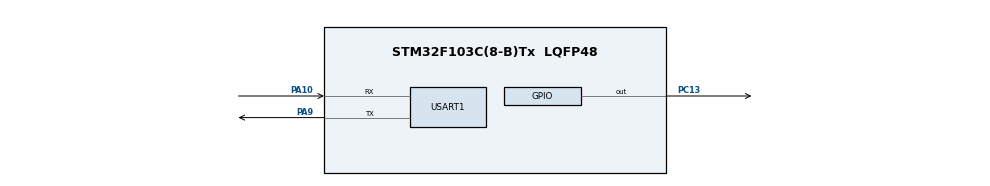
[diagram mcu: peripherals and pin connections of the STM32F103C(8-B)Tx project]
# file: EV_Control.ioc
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Mcu.Family=STM32F1
Mcu.Name=STM32F103C(8-B)Tx
Mcu.Package=LQFP48
NVIC.PriorityGroup=NVIC_PRIORITYGROUP_4
PA10.Mode=Asynchronous
PA10.Signal=USART1_RX
PA9.Mode=Asynchronous
PA9.Signal=USART1_TX
PC13-TAMPER-RTC.Signal=GPIO_Output
ProjectManager.HeapSize=0x200
ProjectManager.StackSize=0x400
ProjectManager.TargetToolchain=STM32CubeIDE
RCC.APB1Freq_Value=8000000
RCC.APB2Freq_Value=8000000
USART1.VirtualMode=VM_ASYNC
VP_SYS_VS_ND.Mode=No_Debug
board=custom

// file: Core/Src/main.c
/* USER CODE BEGIN Header */
/**
  ******************************************************************************
  * @file           : main.c
  * @brief          : Main program body
  ******************************************************************************
  * @attention
  *
  * Copyright (c) 2026 STMicroelectronics.
  * All rights reserved.
  *
  * This software is licensed under terms that can be found in the LICENSE file
  * in the root directory of this software component.
  * If no LICENSE file comes with this software, it is provided AS-IS.
  *
  ******************************************************************************
  */
/* USER CODE END Header */
#include "main.h"

/* USER CODE BEGIN Includes */
#include "ev_control.h"
#include <stdio.h>
/* USER CODE END Includes */

UART_HandleTypeDef huart1;

/* USER CODE BEGIN PV */
EV_State_t ev;
static uint32_t uart_counter = 0;
/* USER CODE END PV */

void SystemClock_Config(void);
static void MX_GPIO_Init(void);
static void MX_USART1_UART_Init(void);
/* USER CODE BEGIN PFP */
static void UART_Print_EV_State(float accel_pct, float brake_pct);
static const char* DriveMode_ToString(DriveMode_t mode);
/* USER CODE END PFP */

int main(void)
{

  /* MCU Configuration--------------------------------------------------------*/

  /* Reset of all peripherals, Initializes the Flash interface and the Systick. */
  HAL_Init();

  /* Configure the system clock */
  SystemClock_Config();

  /* Initialize all configured peripherals */
  MX_GPIO_Init();
  MX_USART1_UART_Init();
  /* USER CODE BEGIN 2 */
  EV_Init(&ev);

  const char start_msg[] = "EV_Control demo started\r\n";
  HAL_UART_Transmit(&huart1, (uint8_t*)start_msg, sizeof(start_msg) - 1U, 100);
  /* USER CODE END 2 */

  /* Infinite loop */
  while (1)
  {

    /* USER CODE BEGIN 3 */
    uint32_t phase_ms;
    float accel_pct;
    float brake_pct;

    phase_ms = HAL_GetTick() % 28000U;

    if (phase_ms < 8000U)
    {
      EV_SetDriveMode(&ev, DRIVE_NORMAL);
      accel_pct = 50.0f;
      brake_pct = 0.0f;
    }
    else if (phase_ms < 12000U)
    {
      EV_SetDriveMode(&ev, DRIVE_NORMAL);
      accel_pct = 0.0f;
      brake_pct = 80.0f;
    }
    else if (phase_ms < 20000U)
    {
      EV_SetDriveMode(&ev, DRIVE_SPORT);
      accel_pct = 70.0f;
      brake_pct = 0.0f;
    }
    else
    {
      EV_SetDriveMode(&ev, DRIVE_ECO);
      accel_pct = 40.0f;
      brake_pct = 0.0f;
    }

    EV_Update(&ev, accel_pct, brake_pct, 0.01f);

    uart_counter++;
    if (uart_counter >= 50U)
    {
      uart_counter = 0U;
      HAL_GPIO_TogglePin(GPIOC, GPIO_PIN_13);
      UART_Print_EV_State(accel_pct, brake_pct);
    }

    HAL_Delay(10);
  }
  /* USER CODE END 3 */
}

void SystemClock_Config(void)
{
  RCC_OscInitTypeDef RCC_OscInitStruct = {0};
  RCC_ClkInitTypeDef RCC_ClkInitStruct = {0};

  /** Initializes the RCC Oscillators according to the specified parameters
  * in the RCC_OscInitTypeDef structure.
  */
  RCC_OscInitStruct.OscillatorType = RCC_OSCILLATORTYPE_HSI;
  RCC_OscInitStruct.HSIState = RCC_HSI_ON;
  RCC_OscInitStruct.HSICalibrationValue = RCC_HSICALIBRATION_DEFAULT;
  RCC_OscInitStruct.PLL.PLLState = RCC_PLL_NONE;
  if (HAL_RCC_OscConfig(&RCC_OscInitStruct) != HAL_OK)
  {
    Error_Handler();
  }

  /** Initializes the CPU, AHB and APB buses clocks
  */
  RCC_ClkInitStruct.ClockType = RCC_CLOCKTYPE_HCLK|RCC_CLOCKTYPE_SYSCLK
                              |RCC_CLOCKTYPE_PCLK1|RCC_CLOCKTYPE_PCLK2;
  RCC_ClkInitStruct.SYSCLKSource = RCC_SYSCLKSOURCE_HSI;
  RCC_ClkInitStruct.AHBCLKDivider = RCC_SYSCLK_DIV1;
  RCC_ClkInitStruct.APB1CLKDivider = RCC_HCLK_DIV1;
  RCC_ClkInitStruct.APB2CLKDivider = RCC_HCLK_DIV1;

  if (HAL_RCC_ClockConfig(&RCC_ClkInitStruct, FLASH_LATENCY_0) != HAL_OK)
  {
    Error_Handler();
  }
}

static void MX_USART1_UART_Init(void)
{

  huart1.Instance = USART1;
  huart1.Init.BaudRate = 115200;
  huart1.Init.WordLength = UART_WORDLENGTH_8B;
  huart1.Init.StopBits = UART_STOPBITS_1;
  huart1.Init.Parity = UART_PARITY_NONE;
  huart1.Init.Mode = UART_MODE_TX_RX;
  huart1.Init.HwFlowCtl = UART_HWCONTROL_NONE;
  huart1.Init.OverSampling = UART_OVERSAMPLING_16;
  if (HAL_UART_Init(&huart1) != HAL_OK)
  {
    Error_Handler();
  }

}

static void MX_GPIO_Init(void)
{
  GPIO_InitTypeDef GPIO_InitStruct = {0};

  /* GPIO Ports Clock Enable */
  __HAL_RCC_GPIOC_CLK_ENABLE();
  __HAL_RCC_GPIOA_CLK_ENABLE();

  /*Configure GPIO pin Output Level */
  HAL_GPIO_WritePin(GPIOC, GPIO_PIN_13, GPIO_PIN_RESET);

  /*Configure GPIO pin : PC13 */
  GPIO_InitStruct.Pin = GPIO_PIN_13;
  GPIO_InitStruct.Mode = GPIO_MODE_OUTPUT_PP;
  GPIO_InitStruct.Pull = GPIO_NOPULL;
  GPIO_InitStruct.Speed = GPIO_SPEED_FREQ_LOW;
  HAL_GPIO_Init(GPIOC, &GPIO_InitStruct);

}

/* USER CODE BEGIN 4 */
static void UART_Print_EV_State(float accel_pct, float brake_pct)
{
  char msg[220];

  int len = snprintf(
      msg,
      sizeof(msg),
      "MODE=%s | ACCEL=%3.0f%% | BRAKE=%3.0f%% | SPD=%6.2f km/h | TRQ=%7.2f Nm | SOC=%6.2f%% | RNG=%7.2f km | PWR=%7.2f kW | TEMP=%6.2f C | REGEN=%d\r\n",
      DriveMode_ToString(ev.drive_mode),
      accel_pct,
      brake_pct,
      ev.speed_kmh,
      ev.torque_Nm,
      ev.soc_pct,
      ev.range_km,
      ev.power_kW,
      ev.motor_temp_C,
      ev.regen_active);

  if (len > 0)
  {
    HAL_UART_Transmit(&huart1, (uint8_t*)msg, (uint16_t)len, 100);
  }
}

static const char* DriveMode_ToString(DriveMode_t mode)
{
  switch (mode)
  {
    case DRIVE_ECO:
      return "ECO";

    case DRIVE_SPORT:
      return "SPORT";

    case DRIVE_NORMAL:
    default:
      return "NORMAL";
  }
}
/* USER CODE END 4 */

void Error_Handler(void)
{
  /* USER CODE BEGIN Error_Handler_Debug */
  /* User can add his own implementation to report the HAL error return state */
  __disable_irq();
  while (1)
  {
    HAL_GPIO_TogglePin(GPIOC, GPIO_PIN_13);
    HAL_Delay(100);
  }
  /* USER CODE END Error_Handler_Debug */
}
